# GD32H77x_78x register map
File version: 1.0
CPU: CM7 r1p2, little endian, MPU, FPU, 4 interrupt priority bits
Registers are 32-bit, read-write, reset 0x0 unless marked. A register's access mark holds for its fields unless they carry their own. Offsets are from the block's base; [hi:lo] are bit positions; {n}, {i} and the like mark numbered series.

## TFMT — Tamagawa format encoder interface module
Base 0x4000C800
0x00 DATAID — TFMT ID code register
  [3:0] CC — Data ID code
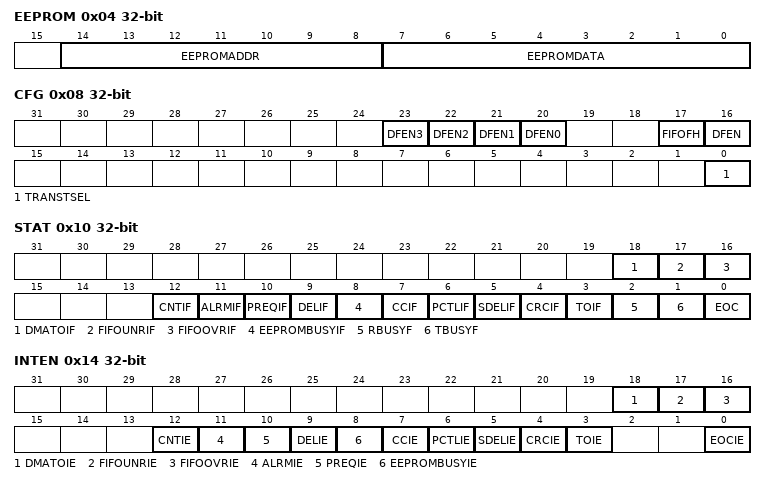
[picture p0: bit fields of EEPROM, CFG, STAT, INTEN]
0x04 EEPROM — TFMT EEPROM register
  [14:8] EEPROMADDR — EEPROM accessing address of encoder
  [7:0] EEPROMDATA — Data to be written into EEPROM of encoder
0x08 CFG access per field — TFMT configuration register
  [n+20] DFEN{n} rw (n=0..3) — DMA request and FIFO enable for EDIM_TFMT_RDATA{n} register
  [17] FIFOFH wo — FIFO flush
  [16] DFEN rw — DMA request and FIFO enable
  [0] TRANSTSEL rw — Transmission start trigger selection
0x0C SWT wo — TFMT software trigger register
  [0] SWTR — Data transmission software trigger, cleared by hardware
0x10 STAT — TFMT status register
  [18] DMATOIF — DMA request timeout error interrupt flag
  [17] FIFOUNRIF — FIFO underrun error interrupt flag
  [16] FIFOOVRIF — FIFO overrun error interrupt flag
  [12] CNTIF — Counting error interrupt flag of encoder
  [11] ALRMIF — Alarm interrupt flag of encoder
  [10] PREQIF — Parity error interrupt flag in request frame
  [9] DELIF — Delimiter error interrupt flag in request frame
  [8] EEPROMBUSYIF — EEPROM busy interrupt flag
  [7] CCIF — Data ID code error interrupt flag
  [6] PCTLIF — Parity error interrupt flag in received control field of frame
  [5] SDELIF — Start bit error interrupt flag or delimiter error flag in received frame
  [4] CRCIF — CRC error interrupt flag in received frame
  [3] TOIF — Encoder transmission timeout error interrupt flag
  [2] RBUSYF — Receive busy flag
  [1] TBUSYF — Transmit busy flag
  [0] EOC — End of communication
0x14 INTEN — TFMT interrupt enable register
  [18] DMATOIE — Interrupt enable of DMATOIF
  [17] FIFOUNRIE — Interrupt enable of FIFOUNRIF
  [16] FIFOOVRIE — Interrupt enable of FIFOOVRIF
  [12] CNTIE — Interrupt enable for CNTIF
  [11] ALRMIE — Interrupt enable for ALRMIF
  [10] PREQIE — Interrupt enable for PREQIF
  [9] DELIE — Interrupt enable for DELIF
  [8] EEPROMBUSYIE — Interrupt enable for EEPROMBUSYIF
  [7] CCIE — Interrupt enable for CCIF
  [6] PCTLIE — Interrupt enable for PCTLIF
  [5] SDELIE — Interrupt enable for SDELIF
  [4] CRCIE — Interrupt enable for CRCIF
  [3] TOIE — Interrupt enable for TOIF
  [0] EOCIE — Interrupt enable for EOC
{0x18+4i} RDATA{i} ro (i=0..3) — TFMT received data register {i}
  [31:0] RDATA — Received data from encoder

## TIMER5 — Basic-timers
Base 0x40001000
Same registers: TIMER6 0x40001400
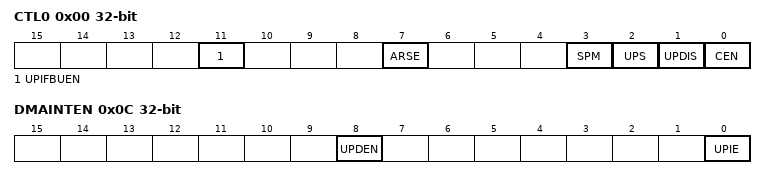
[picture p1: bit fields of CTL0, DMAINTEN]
0x00 CTL0 — control register 0
  [11] UPIFBUEN — UPIF bit backup enable
  [7] ARSE — Auto-reload preload enable
  [3] SPM — One-pulse mode
  [2] UPS — Update request source
  [1] UPDIS — Update disable
  [0] CEN — Counter enable
0x04 CTL1 — control register 1
  [6:4] MMC0 — Master mode selection
0x0C DMAINTEN — DMA/Interrupt enable register
  [8] UPDEN — Update DMA request enable
  [0] UPIE — Update interrupt enable
0x10 INTF — status register
  [0] UPIF — Update interrupt flag
0x14 SWEVG wo — event generation register
  [0] UPG — Update generation
0x24 CNT — counter
  [31:0] CNT — Low counter value
0x28 PSC — prescaler
  [15:0] PSC — Prescaler value
0x2C CARL — Counter auto-reload low register
  [31:0] CARL — Low Auto-reload value

## TIMER50 — Basic-timers
Base 0x4000F000
Same registers: TIMER51 0x4000F400
Registers as TIMER5, without CNT; these are added or differ:
0x24 CNTL — counter
  [31:0] CNTL — Low counter value
0x2C CARL — Counter auto-reload low register
  [31:0] CARLL — Low Auto-reload value
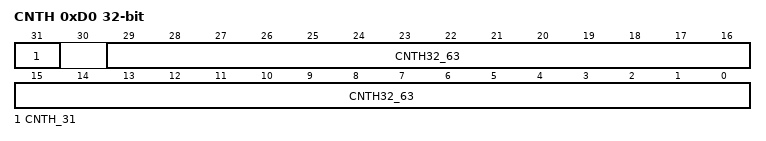
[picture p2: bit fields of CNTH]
0xD0 CNTH — Counter high register
  [31] CNTH_31, [29:0] CNTH32_63
0xD4 CARH — Counter high register
  [31:0] CARLH32_63

## TMU — Trigonometric Math Unit
Base 0x48024400
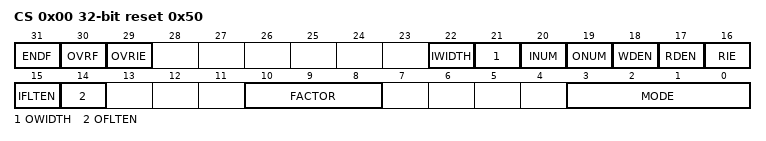
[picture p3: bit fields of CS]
0x00 CS access per field reset 0x50 — Control and status register
  [31] ENDF ro — End of TMU operation flag
  [30] OVRF ro — The flag of overflow
  [29] OVRIE ro — Overflow interrupt enable
  [22] IWIDTH rw — Width of input data
  [21] OWIDTH rw — Width of output data
  [20] INUM rw — The number of times that the IDATA needs to be written
  [19] ONUM rw — The number of times that the ODATA needs to be read
  [18] WDEN rw — Enable DMA request to write IDATA
  [17] RDEN rw — Enable DMA request to read ODATA
  [16] RIE rw — Enable interrupt request to read ODATA
  [15] IFLTEN rw — Input floating point format enable
  [14] OFLTEN rw — Output floating point format enable
  [10:8] FACTOR rw — Scaling factor
  [3:0] MODE rw — Mode of CORDIC operation
0x04 IDATA wo — Input data register
  [31:0] IDATA — The input data
0x08 ODATA ro — Output Data register
  [31:0] ODATA — The output data

## TRNG — True random number generator
Base 0x48021800
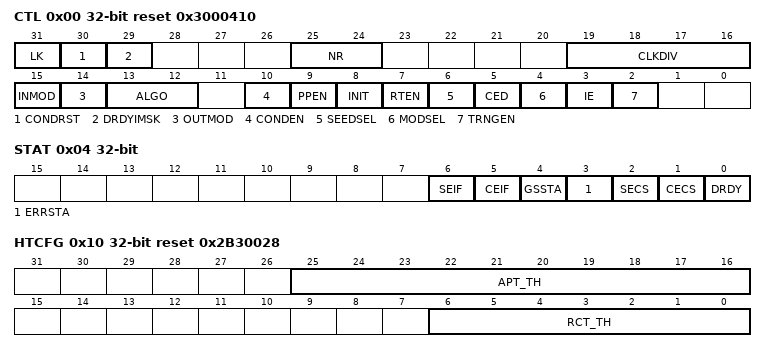
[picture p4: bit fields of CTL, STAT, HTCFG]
0x00 CTL access per field reset 0x3000410 — Control register
  [31] LK ro — TRNG_CTL register lock bit
  [30] CONDRST rw — reset conditioning logic
  [29] DRDYIMSK rw — DRDY interrupt mask bit.
  [25:24] NR rw — analog trng power mode
  [19:16] CLKDIV rw — TRNG clock divider
  [15] INMOD rw — select random seed number input to conditioning module
  [14] OUTMOD rw — select random data width output of conditioning module
  [13:12] ALGO rw — None NIST compliant
  [10] CONDEN rw — enable conditioning component
  [9] PPEN rw — enable post_processing
  [8] INIT rw — init hash algo when conditioning enabled
  [7] RTEN rw — replace test enable bit
  [6] SEEDSEL rw — NIST mode source of seed selection
  [5] CED rw — clock error detection
  [4] MODSEL rw — LFSR or NIST mode selection
  [3] IE rw — Interrupt enabled bit
  [2] TRNGEN rw — TRNG enabled bit
0x04 STAT access per field — Status register
  [6] SEIF rw — Seed error interrupt flag
  [5] CEIF rw — Clock error interrupt flag
  [4] GSSTA rw — the module is in generating random number sample state
  [3] ERRSTA rw — NIST mode error flag, this bit could be reset by CONDRST
  [2] SECS ro — Seed error current status
  [1] CECS ro — Clock error current status
  [0] DRDY ro — Random data ready status bit
0x08 DATA ro
  [31:0] TRNDATA — 32-bit random data
0x10 HTCFG reset 0x2B30028 — Health tests configure register
  [25:16] APT_TH — Adaptive proportion test threshold
  [6:0] RCT_TH — Repetition count test threshold

## USBHS0_PWRCLK — USB on the go high speed
Base 0x40040E00
Same registers: USBHS1_PWRCLK 0x40080E00
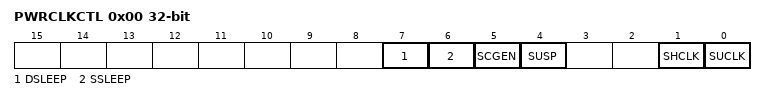
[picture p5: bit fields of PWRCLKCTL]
0x00 PWRCLKCTL access per field — power and clock gating control register (PWRCLKCTL)
  [7] DSLEEP ro — PHY is in deep sleep status
  [6] SSLEEP ro — PHY is in shallow sleep status
  [5] SCGEN ro — internal clock gating enable
  [4] SUSP ro — PHY is in suspend status
  [1] SHCLK rw — Stop HCLK
  [0] SUCLK rw — Stop the USB clock

## VREF
Base 0x58003C00
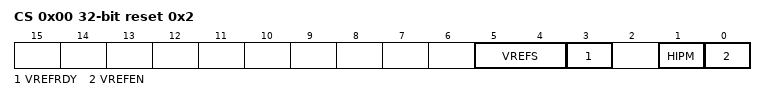
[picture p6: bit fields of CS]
0x00 CS access per field reset 0x2 — Control and status register
  [5:4] VREFS ro — Voltage reference select
  [3] VREFRDY ro — VREF ready
  [1] HIPM rw — High impedance mode
  [0] VREFEN rw — VREF enable
0x04 CALIB — Calibration register
  [5:0] VREFCAL — VREF calibration

## WWDGT — Window watchdog timer
Base 0x50003000
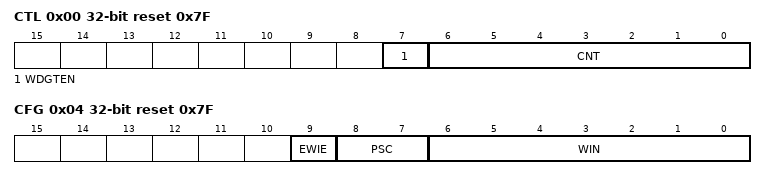
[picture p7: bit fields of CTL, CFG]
0x00 CTL reset 0x7F — Control register
  [7] WDGTEN — Activation bit
  [6:0] CNT — 7-bit counter
0x04 CFG reset 0x7F — Configuration register
  [9] EWIE — Early wakeup interrupt
  [8:7] PSC — Prescaler
  [6:0] WIN — 7-bit window value
0x08 STAT — Status register
  [0] EWIF — Early wakeup interrupt flag
